# S32M24x register map
Vendor: NXP Semiconductors; File version: 1.3
CPU: CM4 r0p1, little endian, MPU, FPU, VTOR, 4 interrupt priority bits
Registers are 32-bit, read-write, reset 0x0 unless marked. A register's access mark holds for its fields unless they carry their own. Offsets are from the block's base; [hi:lo] are bit positions; 'fields as' and 'values as' point back to an identical list.

## RCM
Base 0x4007F000
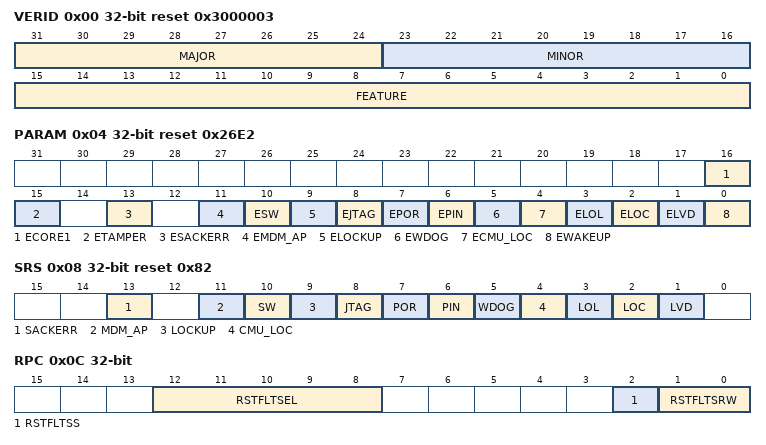
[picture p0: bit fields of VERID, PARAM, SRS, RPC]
0x00 VERID ro reset 0x3000003 — Version ID Register
  [31:24] MAJOR — Major Version Number
  [23:16] MINOR — Minor Version Number
  [15:0] FEATURE — Feature Specification Number
    3=Standard feature set
0x04 PARAM ro reset 0x26E2 — Parameter Register
  [all] fields
    0=The feature is not available; 1=The feature is available
  [16] ECORE1 — Existence of SRS[CORE1] status indication feature
  [15] ETAMPER — Existence of SRS[TAMPER] status indication feature
  [13] ESACKERR — Existence of SRS[SACKERR] status indication feature
  [11] EMDM_AP — Existence of SRS[MDM_AP] status indication feature
  [10] ESW — Existence of SRS[SW] status indication feature
  [9] ELOCKUP — Existence of SRS[LOCKUP] status indication feature
  [8] EJTAG — Existence of SRS[JTAG] status indication feature
  [7] EPOR — Existence of SRS[POR] status indication feature
  [6] EPIN — Existence of SRS[PIN] status indication feature
  [5] EWDOG — Existence of SRS[WDOG] status indication feature
  [4] ECMU_LOC — Existence of SRS[CMU_LOC] status indication feature
  [3] ELOL — Existence of SRS[LOL] status indication feature
  [2] ELOC — Existence of SRS[LOC] status indication feature
  [1] ELVD — Existence of SRS[LVD] status indication feature
  [0] EWAKEUP — Existence of SRS[WAKEUP] status indication feature
0x08 SRS ro reset 0x82 — System Reset Status Register
  [13] SACKERR — Stop Acknowledge Error
    0=Reset not caused by peripheral failure to acknowledge attempt to enter stop mode; 1=Reset caused by peripheral failure to acknowledge attempt to enter stop mode
  [11] MDM_AP — MDM-AP System Reset Request
    0=Reset was not caused by host debugger system setting of the System Reset Request bit; 1=Reset was caused by host debugger system setting of the System Reset Request bit
  [10] SW — Software
    0=Reset not caused by software setting of SYSRESETREQ bit; 1=Reset caused by software setting of SYSRESETREQ bit
  [9] LOCKUP — Core Lockup
    0=Reset not caused by core LOCKUP event; 1=Reset caused by core LOCKUP event
  [8] JTAG — JTAG generated reset
    0=Reset not caused by JTAG; 1=Reset caused by JTAG
  [7] POR — Power-On Reset
    0=Reset not caused by POR; 1=Reset caused by POR
  [6] PIN — External Reset Pin
    0=Reset not caused by external reset pin; 1=Reset caused by external reset pin
  [5] WDOG — Watchdog
    0=Reset not caused by watchdog timeout; 1=Reset caused by watchdog timeout
  [4] CMU_LOC — CMU Loss-of-Clock Reset
    0=Reset not caused by the CMU loss-of-clock circuit; 1=Reset caused by the CMU loss-of-clock circuit
  [3] LOL — Loss-of-Lock Reset
    0=Reset not caused by a loss of lock in the PLL/FLL; 1=Reset caused by a loss of lock in the PLL/FLL
  [2] LOC — Loss-of-Clock Reset
    0=Reset not caused by a loss of external clock; 1=Reset caused by a loss of external clock
  [1] LVD — Low-Voltage Detect Reset or High-Voltage Detect Reset
    0=Reset not caused by LVD trip, HVD trip or POR; 1=Reset caused by LVD trip, HVD trip or POR
0x0C RPC — Reset Pin Control register
  [12:8] RSTFLTSEL — Reset Pin Filter Bus Clock Select
  [2] RSTFLTSS — Reset Pin Filter Select in Stop Mode
    0=All filtering disabled; 1=LPO clock filter enabled
  [1:0] RSTFLTSRW — Reset Pin Filter Select in Run and Wait Modes
    0=All filtering disabled; 1=Bus clock filter enabled for normal operation; 2=LPO clock filter enabled for normal operation
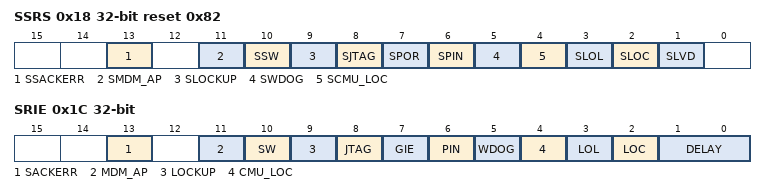
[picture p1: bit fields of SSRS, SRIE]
0x18 SSRS reset 0x82 write-1-clears — Sticky System Reset Status Register
  [13] SSACKERR write-1-clears — Sticky Stop Acknowledge Error
    values as SRS.SACKERR
  [11] SMDM_AP write-1-clears — Sticky MDM-AP System Reset Request
    values as SRS.MDM_AP
  [10] SSW write-1-clears — Sticky Software
    values as SRS.SW
  [9] SLOCKUP write-1-clears — Sticky Core Lockup
    values as SRS.LOCKUP
  [8] SJTAG write-1-clears — Sticky JTAG generated reset
    0=Reset not caused by JTAG; 1=Reset caused by JTAG
  [7] SPOR write-1-clears — Sticky Power-On Reset
    0=Reset not caused by POR; 1=Reset caused by POR
  [6] SPIN write-1-clears — Sticky External Reset Pin
    values as SRS.PIN
  [5] SWDOG write-1-clears — Sticky Watchdog
    values as SRS.WDOG
  [4] SCMU_LOC write-1-clears — Sticky CMU Loss-of-Clock Reset
    values as SRS.CMU_LOC
  [3] SLOL write-1-clears — Sticky Loss-of-Lock Reset
    values as SRS.LOL
  [2] SLOC write-1-clears — Sticky Loss-of-Clock Reset
    values as SRS.LOC
  [1] SLVD write-1-clears — Sticky Low-Voltage Detect Reset
    0=Reset not caused by LVD trip or POR; 1=Reset caused by LVD trip or POR
0x1C SRIE — System Reset Interrupt Enable Register
  [13] SACKERR — Stop Acknowledge Error Interrupt
    0=Interrupt disabled; 1=Interrupt enabled
  [11] MDM_AP — MDM-AP System Reset Request
    0=Interrupt disabled; 1=Interrupt enabled
  [10] SW — Software Interrupt
    0=Interrupt disabled; 1=Interrupt enabled
  [9] LOCKUP — Core Lockup Interrupt
    0=Interrupt disabled; 1=Interrupt enabled
  [8] JTAG — JTAG generated reset
    0=Interrupt disabled; 1=Interrupt enabled
  [7] GIE — Global Interrupt Enable
    0=All interrupt sources disabled; 1=All interrupt sources enabled. Note that the individual interrupt-enable bits still need to be set to generate interrupts.
  [6] PIN — External Reset Pin Interrupt
    values as SRS.PIN
  [5] WDOG — Watchdog Interrupt
    0=Interrupt disabled; 1=Interrupt enabled
  [4] CMU_LOC — CMU Loss-of-Clock Interrupt
    0=Interrupt disabled; 1=Interrupt enabled
  [3] LOL — Loss-of-Lock Interrupt
    0=Interrupt disabled; 1=Interrupt enabled
  [2] LOC — Loss-of-Clock Interrupt
    0=Interrupt disabled; 1=Interrupt enabled
  [1:0] DELAY — Reset Delay Time
    0=10 LPO cycles; 1=34 LPO cycles; 2=130 LPO cycles; 3=514 LPO cycles
